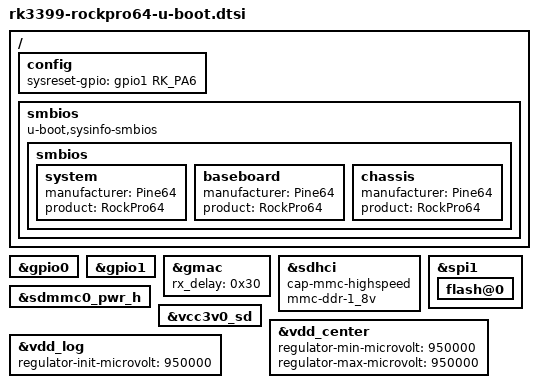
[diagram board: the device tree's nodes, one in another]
// SPDX-License-Identifier: GPL-2.0+
/*
 * Copyright (C) 2019 Jagan Teki <jagan@amarulasolutions.com>
 */

#include "rk3399-u-boot.dtsi"
#include "rk3399-sdram-lpddr4-100.dtsi"

/ {
	config {
		sysreset-gpio = <&gpio1 RK_PA6 GPIO_ACTIVE_HIGH>;
	};

        smbios {
                compatible = "u-boot,sysinfo-smbios";
                smbios {
                        system {
                                manufacturer = "Pine64";
                                product = "RockPro64";
                        };

                        baseboard {
                                manufacturer = "Pine64";
                                product = "RockPro64";
                        };

                        chassis {
                                manufacturer = "Pine64";
                                product = "RockPro64";
                        };
                };
        };
};

&gpio0 {
	bootph-pre-ram;
};

&gpio1 {
	bootph-pre-ram;
};

&gmac {
	/*
	 * The upstream rx_delay of 0x11 sits on the very edge of this board's
	 * RGMII receive window.  Sweeping the delay while counting
	 * mmc_rx_crc_error and large-ping loss shows 0x00-0x10 failing
	 * completely, 0x11 marginal (5% loss on 1400-byte pings) and
	 * 0x14-0x50 entirely clean, with 0x60 upwards failing again.  Use the
	 * middle of that window.
	 */
	rx_delay = <0x30>;
};

&sdhci {
	cap-mmc-highspeed;
	mmc-ddr-1_8v;
};

&sdmmc0_pwr_h {
	bootph-pre-ram;
};

&spi1 {
	flash@0 {
		bootph-pre-ram;
		bootph-some-ram;
	};
};

&vcc3v0_sd {
	bootph-pre-ram;
};

&vdd_center {
	regulator-min-microvolt = <950000>;
	regulator-max-microvolt = <950000>;
};

&vdd_log {
	regulator-init-microvolt = <950000>;
};
